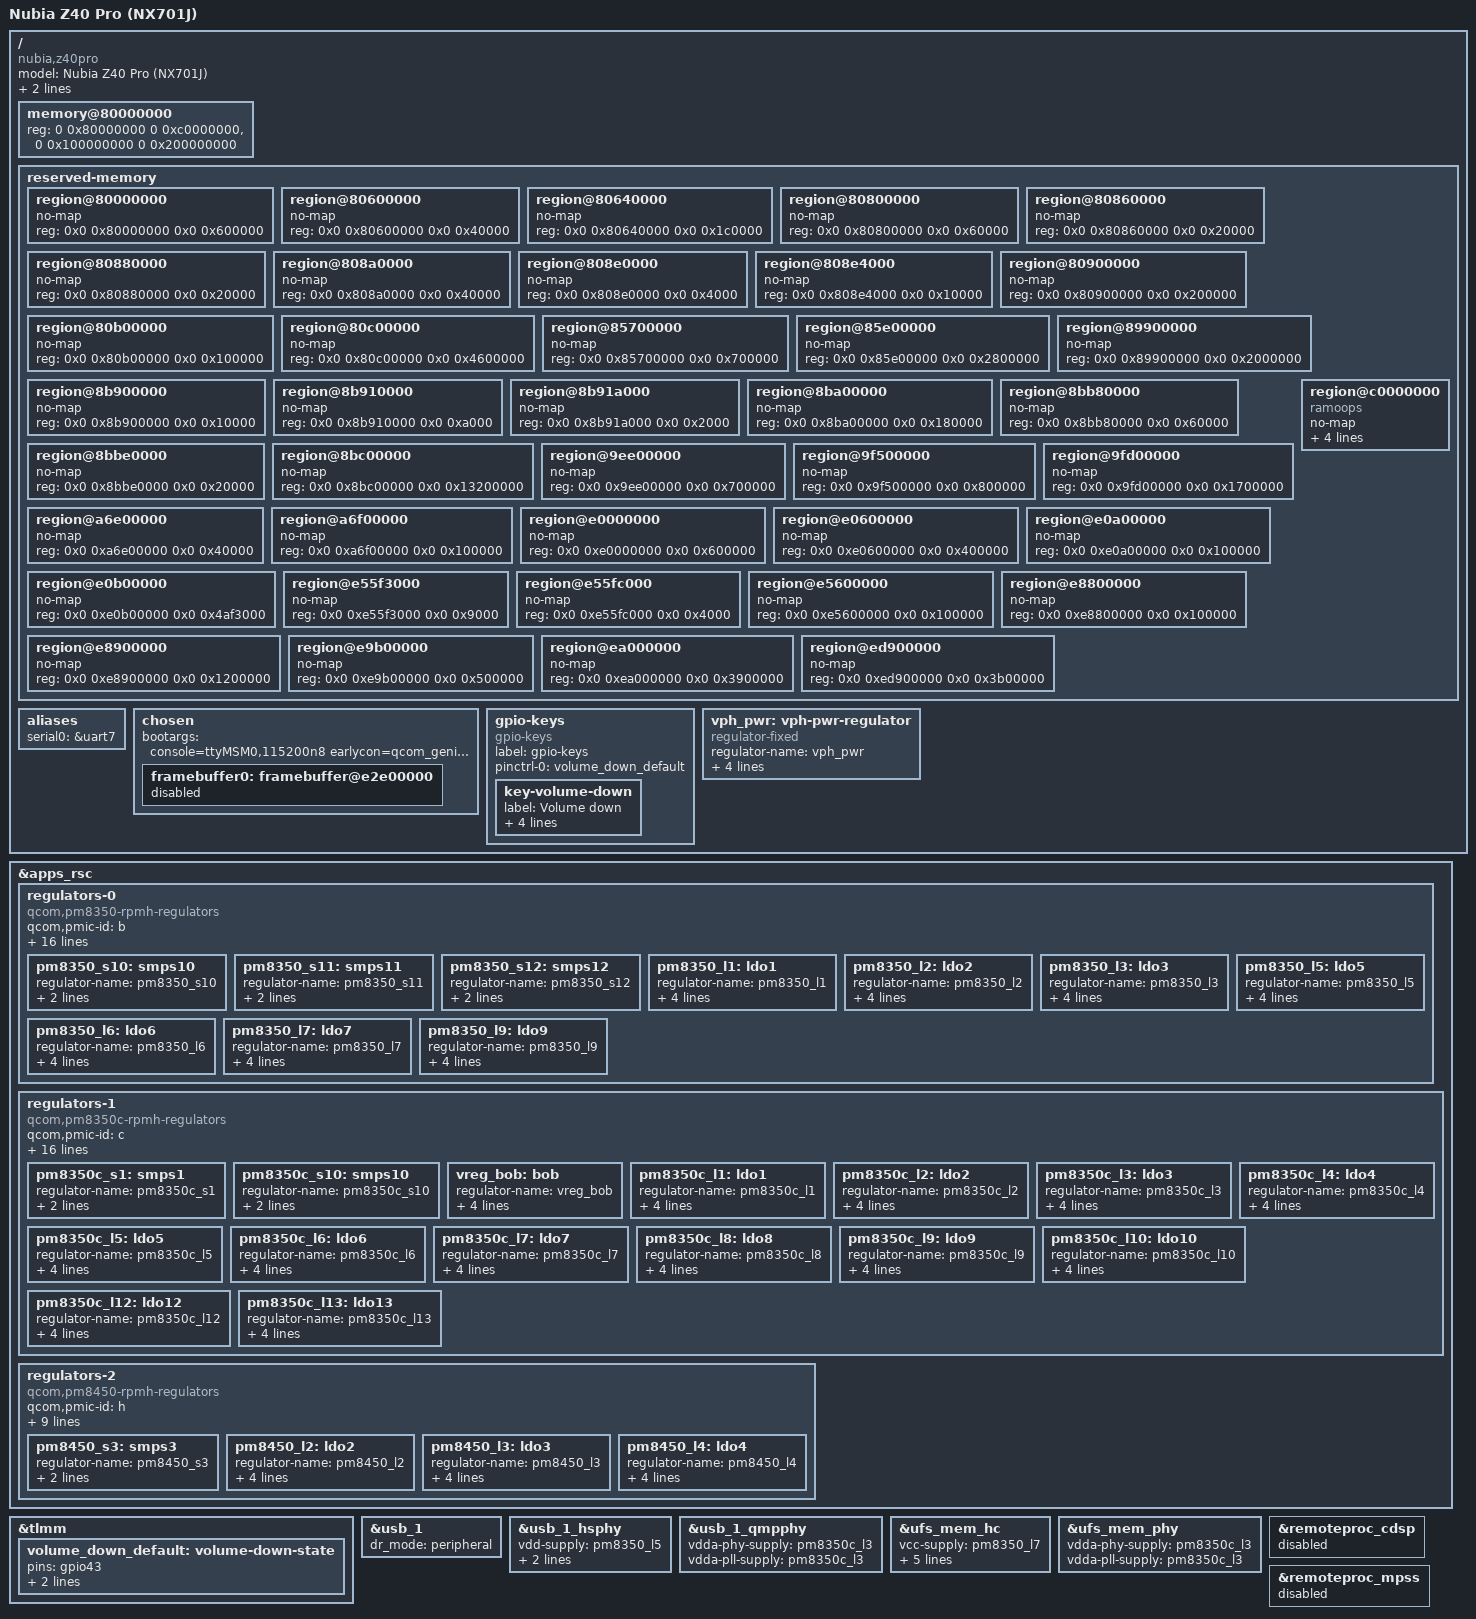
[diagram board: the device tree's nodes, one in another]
// SPDX-License-Identifier: BSD-3-Clause
/*
 * Nubia Z40 Pro (NX701J) — 骁龙8 Gen 1 (SM8450)
 * 底稿: sm8450-sony-xperia-nagara.dtsi (同平台手机模板)
 * 面板: Visionox RM692E5 1080p DSC cmd (mainline panel-visionox-rm692e5, M5 点亮)
 * 触摸: FocalTech (M5 移植)
 * v0.1 目标: USB/UFS 心跳 — 不含面板/触摸/音频/相机
 */

/dts-v1/;

#include "sm8450.dtsi"
#include "pm8350.dtsi"
#include "pm8350b.dtsi"
#include "pm8350c.dtsi"
#include "pm8450.dtsi"
#include <dt-bindings/input/linux-event-codes.h>
#include <dt-bindings/regulator/qcom,rpmh-regulator.h>

/ {
	model = "Nubia Z40 Pro (NX701J)";
	compatible = "nubia,z40pro", "qcom,sm8450";

	/* ZTE ABL 板级匹配必需 (从 MyOS cape DT 提取) */
	qcom,msm-id = <0x21c 0x10000>;
	qcom,board-id = <0x0 0x0>;

	memory@80000000 {
		device_type = "memory";
		/* Z40 Pro 12GB: 3GB @0x80000000 + 8GB @0x100000000 */
		reg = <0 0x80000000 0 0xc0000000>,
		      <0 0x100000000 0 0x200000000>;
	};

	reserved-memory {
		#address-cells = <2>;
		#size-cells = <2>;
		ranges;

		region@80000000 {
			no-map;
			reg = <0x0 0x80000000 0x0 0x600000>;
		};

		region@80600000 {
			no-map;
			reg = <0x0 0x80600000 0x0 0x40000>;
		};

		region@80640000 {
			no-map;
			reg = <0x0 0x80640000 0x0 0x1c0000>;
		};

		region@80800000 {
			no-map;
			reg = <0x0 0x80800000 0x0 0x60000>;
		};

		region@80860000 {
			no-map;
			reg = <0x0 0x80860000 0x0 0x20000>;
		};

		region@80880000 {
			no-map;
			reg = <0x0 0x80880000 0x0 0x20000>;
		};

		region@808a0000 {
			no-map;
			reg = <0x0 0x808a0000 0x0 0x40000>;
		};

		region@808e0000 {
			no-map;
			reg = <0x0 0x808e0000 0x0 0x4000>;
		};

		region@808e4000 {
			no-map;
			reg = <0x0 0x808e4000 0x0 0x10000>;
		};

		region@80900000 {
			no-map;
			reg = <0x0 0x80900000 0x0 0x200000>;
		};

		region@80b00000 {
			no-map;
			reg = <0x0 0x80b00000 0x0 0x100000>;
		};

		region@80c00000 {
			no-map;
			reg = <0x0 0x80c00000 0x0 0x4600000>;
		};

		region@85700000 {
			no-map;
			reg = <0x0 0x85700000 0x0 0x700000>;
		};

		region@85e00000 {
			no-map;
			reg = <0x0 0x85e00000 0x0 0x2800000>;
		};

		region@89900000 {
			no-map;
			reg = <0x0 0x89900000 0x0 0x2000000>;
		};

		region@8b900000 {
			no-map;
			reg = <0x0 0x8b900000 0x0 0x10000>;
		};

		region@8b910000 {
			no-map;
			reg = <0x0 0x8b910000 0x0 0xa000>;
		};

		region@8b91a000 {
			no-map;
			reg = <0x0 0x8b91a000 0x0 0x2000>;
		};

		region@8ba00000 {
			no-map;
			reg = <0x0 0x8ba00000 0x0 0x180000>;
		};

		region@8bb80000 {
			no-map;
			reg = <0x0 0x8bb80000 0x0 0x60000>;
		};

		region@8bbe0000 {
			no-map;
			reg = <0x0 0x8bbe0000 0x0 0x20000>;
		};

		region@8bc00000 {
			no-map;
			reg = <0x0 0x8bc00000 0x0 0x13200000>;
		};

		region@9ee00000 {
			no-map;
			reg = <0x0 0x9ee00000 0x0 0x700000>;
		};

		region@9f500000 {
			no-map;
			reg = <0x0 0x9f500000 0x0 0x800000>;
		};

		region@9fd00000 {
			no-map;
			reg = <0x0 0x9fd00000 0x0 0x1700000>;
		};

		region@a6e00000 {
			no-map;
			reg = <0x0 0xa6e00000 0x0 0x40000>;
		};

		region@a6f00000 {
			no-map;
			reg = <0x0 0xa6f00000 0x0 0x100000>;
		};

		region@c0000000 {
			compatible = "ramoops";
			no-map;
			reg = <0x0 0xc0000000 0x0 0x200000>;
			console-size = <0x40000>;
			record-size = <0x1000>;
			ecc-size = <16>;
		};

		region@e0000000 {
			no-map;
			reg = <0x0 0xe0000000 0x0 0x600000>;
		};

		region@e0600000 {
			no-map;
			reg = <0x0 0xe0600000 0x0 0x400000>;
		};

		region@e0a00000 {
			no-map;
			reg = <0x0 0xe0a00000 0x0 0x100000>;
		};

		region@e0b00000 {
			no-map;
			reg = <0x0 0xe0b00000 0x0 0x4af3000>;
		};

		region@e55f3000 {
			no-map;
			reg = <0x0 0xe55f3000 0x0 0x9000>;
		};

		region@e55fc000 {
			no-map;
			reg = <0x0 0xe55fc000 0x0 0x4000>;
		};

		region@e5600000 {
			no-map;
			reg = <0x0 0xe5600000 0x0 0x100000>;
		};

		region@e8800000 {
			no-map;
			reg = <0x0 0xe8800000 0x0 0x100000>;
		};

		region@e8900000 {
			no-map;
			reg = <0x0 0xe8900000 0x0 0x1200000>;
		};

		region@e9b00000 {
			no-map;
			reg = <0x0 0xe9b00000 0x0 0x500000>;
		};

		region@ea000000 {
			no-map;
			reg = <0x0 0xea000000 0x0 0x3900000>;
		};

		region@ed900000 {
			no-map;
			reg = <0x0 0xed900000 0x0 0x3b00000>;
		};

	};

	aliases {
		serial0 = &uart7;   /* TODO: 确认 Z40 Pro debug uart 实际编号 */
	};

	chosen {
		#address-cells = <1>;
		#size-cells = <1>;
		ranges;
		/* ZTE ABL 的 cmdline 被内建 DTB 覆盖丢弃, bootargs 必须在此 */
		bootargs = "console=ttyMSM0,115200n8 earlycon=qcom_geni,0xa90000 panic=10 loglevel=7 keep_bootcon z40pro.fb=0xB8000000,4320,2400,1080,32";

		framebuffer0: framebuffer@e2e00000 {
			status = "disabled";   /* M5 点亮后启用 */
		};
	};

	/* 音量下键 — GPIO 编号待从 MyOS 运行时确认 (M4 补), 先留壳 */
	gpio-keys {
		compatible = "gpio-keys";
		label = "gpio-keys";
		pinctrl-names = "default";
		pinctrl-0 = <&volume_down_default>;

		key-volume-down {
			label = "Volume down";
			linux,code = <KEY_VOLUMEDOWN>;
			gpios = <&tlmm 43 GPIO_ACTIVE_LOW>;   /* TODO: 校准 */
			debounce-interval = <15>;
			wakeup-source;
		};
	};

	vph_pwr: vph-pwr-regulator {
		compatible = "regulator-fixed";
		regulator-name = "vph_pwr";
		regulator-min-microvolt = <3700000>;
		regulator-max-microvolt = <3700000>;
		regulator-always-on;
		regulator-boot-on;
	};
};

&apps_rsc {
	regulators-0 {
		compatible = "qcom,pm8350-rpmh-regulators";
		qcom,pmic-id = "b";

		vdd-s1-supply = <&vph_pwr>;
		vdd-s2-supply = <&vph_pwr>;
		vdd-s3-supply = <&vph_pwr>;
		vdd-s4-supply = <&vph_pwr>;
		vdd-s5-supply = <&vph_pwr>;
		vdd-s6-supply = <&vph_pwr>;
		vdd-s7-supply = <&vph_pwr>;
		vdd-s8-supply = <&vph_pwr>;
		vdd-s9-supply = <&vph_pwr>;
		vdd-s10-supply = <&vph_pwr>;
		vdd-s11-supply = <&vph_pwr>;
		vdd-s12-supply = <&vph_pwr>;

		vdd-l1-l4-supply = <&pm8350_s11>;
		vdd-l2-l7-supply = <&vreg_bob>;
		vdd-l3-l5-supply = <&vreg_bob>;
		vdd-l6-l9-l10-supply = <&pm8350_s12>;

		pm8350_s10: smps10 {
			regulator-name = "pm8350_s10";
			regulator-min-microvolt = <1800000>;
			regulator-max-microvolt = <1800000>;
		};

		pm8350_s11: smps11 {
			regulator-name = "pm8350_s11";
			regulator-min-microvolt = <848000>;
			regulator-max-microvolt = <1104000>;
		};

		pm8350_s12: smps12 {
			regulator-name = "pm8350_s12";
			regulator-min-microvolt = <1224000>;
			regulator-max-microvolt = <1400000>;
		};

		pm8350_l1: ldo1 {
			regulator-name = "pm8350_l1";
			regulator-min-microvolt = <912000>;
			regulator-max-microvolt = <920000>;
			regulator-initial-mode = <RPMH_REGULATOR_MODE_HPM>;
		};

		pm8350_l2: ldo2 {
			regulator-name = "pm8350_l2";
			regulator-min-microvolt = <3072000>;
			regulator-max-microvolt = <3072000>;
			regulator-initial-mode = <RPMH_REGULATOR_MODE_HPM>;
		};

		pm8350_l3: ldo3 {
			regulator-name = "pm8350_l3";
			regulator-min-microvolt = <904000>;
			regulator-max-microvolt = <904000>;
			regulator-initial-mode = <RPMH_REGULATOR_MODE_HPM>;
		};

		pm8350_l5: ldo5 {
			regulator-name = "pm8350_l5";
			regulator-min-microvolt = <880000>;
			regulator-max-microvolt = <912000>;
			regulator-initial-mode = <RPMH_REGULATOR_MODE_HPM>;
		};

		pm8350_l6: ldo6 {
			regulator-name = "pm8350_l6";
			regulator-min-microvolt = <1200000>;
			regulator-max-microvolt = <1200000>;
			regulator-initial-mode = <RPMH_REGULATOR_MODE_HPM>;
		};

		pm8350_l7: ldo7 {
			regulator-name = "pm8350_l7";
			regulator-min-microvolt = <2960000>;   /* TODO: Z40 Pro 实测校准 (UFS vcc) */
			regulator-max-microvolt = <2960000>;
			regulator-initial-mode = <RPMH_REGULATOR_MODE_HPM>;
		};

		pm8350_l9: ldo9 {
			regulator-name = "pm8350_l9";
			regulator-min-microvolt = <1200000>;
			regulator-max-microvolt = <1200000>;
			regulator-initial-mode = <RPMH_REGULATOR_MODE_HPM>;
		};
	};

	regulators-1 {
		compatible = "qcom,pm8350c-rpmh-regulators";
		qcom,pmic-id = "c";

		vdd-s1-supply = <&vph_pwr>;
		vdd-s2-supply = <&vph_pwr>;
		vdd-s3-supply = <&vph_pwr>;
		vdd-s4-supply = <&vph_pwr>;
		vdd-s5-supply = <&vph_pwr>;
		vdd-s6-supply = <&vph_pwr>;
		vdd-s7-supply = <&vph_pwr>;
		vdd-s8-supply = <&vph_pwr>;
		vdd-s9-supply = <&vph_pwr>;
		vdd-s10-supply = <&vph_pwr>;

		vdd-l1-l12-supply = <&vreg_bob>;
		vdd-l2-l8-supply = <&vreg_bob>;
		vdd-l3-l4-l5-l7-l13-supply = <&vreg_bob>;
		vdd-l6-l9-l11-supply = <&vreg_bob>;
		vdd-l10-supply = <&pm8350_s12>;

		vdd-bob-supply = <&vph_pwr>;

		pm8350c_s1: smps1 {
			regulator-name = "pm8350c_s1";
			regulator-min-microvolt = <1800000>;
			regulator-max-microvolt = <2024000>;
		};

		pm8350c_s10: smps10 {
			regulator-name = "pm8350c_s10";
			regulator-min-microvolt = <1000000>;
			regulator-max-microvolt = <1100000>;
		};

		vreg_bob: bob {
			regulator-name = "vreg_bob";
			regulator-min-microvolt = <3400000>;
			regulator-max-microvolt = <3960000>;
			regulator-initial-mode = <RPMH_REGULATOR_MODE_AUTO>;
		};

		pm8350c_l1: ldo1 {
			regulator-name = "pm8350c_l1";
			regulator-min-microvolt = <1800000>;
			regulator-max-microvolt = <1800000>;
			regulator-initial-mode = <RPMH_REGULATOR_MODE_HPM>;
		};

		pm8350c_l2: ldo2 {
			regulator-name = "pm8350c_l2";
			regulator-min-microvolt = <1800000>;
			regulator-max-microvolt = <1800000>;
			regulator-initial-mode = <RPMH_REGULATOR_MODE_HPM>;
		};

		pm8350c_l3: ldo3 {
			regulator-name = "pm8350c_l3";
			regulator-min-microvolt = <3296000>;
			regulator-max-microvolt = <3304000>;
			regulator-initial-mode = <RPMH_REGULATOR_MODE_HPM>;
		};

		pm8350c_l4: ldo4 {
			regulator-name = "pm8350c_l4";
			regulator-min-microvolt = <1704000>;
			regulator-max-microvolt = <3000000>;
			regulator-initial-mode = <RPMH_REGULATOR_MODE_HPM>;
		};

		pm8350c_l5: ldo5 {
			regulator-name = "pm8350c_l5";
			regulator-min-microvolt = <1704000>;
			regulator-max-microvolt = <3000000>;
			regulator-initial-mode = <RPMH_REGULATOR_MODE_HPM>;
		};

		pm8350c_l6: ldo6 {
			regulator-name = "pm8350c_l6";
			regulator-min-microvolt = <2960000>;
			regulator-max-microvolt = <2960000>;
			regulator-initial-mode = <RPMH_REGULATOR_MODE_HPM>;
		};

		pm8350c_l7: ldo7 {
			regulator-name = "pm8350c_l7";
			regulator-min-microvolt = <3008000>;
			regulator-max-microvolt = <3008000>;
			regulator-initial-mode = <RPMH_REGULATOR_MODE_HPM>;
		};

		pm8350c_l8: ldo8 {
			regulator-name = "pm8350c_l8";
			regulator-min-microvolt = <1800000>;
			regulator-max-microvolt = <1800000>;
			regulator-initial-mode = <RPMH_REGULATOR_MODE_HPM>;
		};

		pm8350c_l9: ldo9 {
			regulator-name = "pm8350c_l9";
			regulator-min-microvolt = <2960000>;
			regulator-max-microvolt = <2960000>;
			regulator-initial-mode = <RPMH_REGULATOR_MODE_HPM>;
		};

		pm8350c_l10: ldo10 {
			regulator-name = "pm8350c_l10";
			regulator-min-microvolt = <1200000>;
			regulator-max-microvolt = <1200000>;
			regulator-initial-mode = <RPMH_REGULATOR_MODE_HPM>;
		};

		pm8350c_l12: ldo12 {
			regulator-name = "pm8350c_l12";
			regulator-min-microvolt = <1800000>;
			regulator-max-microvolt = <1968000>;
			regulator-initial-mode = <RPMH_REGULATOR_MODE_HPM>;
		};

		pm8350c_l13: ldo13 {
			regulator-name = "pm8350c_l13";
			regulator-min-microvolt = <3000000>;
			regulator-max-microvolt = <3000000>;
			regulator-initial-mode = <RPMH_REGULATOR_MODE_HPM>;
		};
	};

	regulators-2 {
		compatible = "qcom,pm8450-rpmh-regulators";
		qcom,pmic-id = "h";

		vdd-s1-supply = <&vph_pwr>;
		vdd-s2-supply = <&vph_pwr>;
		vdd-s3-supply = <&vph_pwr>;
		vdd-s4-supply = <&vph_pwr>;
		vdd-s5-supply = <&vph_pwr>;
		vdd-s6-supply = <&vph_pwr>;

		vdd-l2-supply = <&vreg_bob>;
		vdd-l3-supply = <&vreg_bob>;
		vdd-l4-supply = <&vreg_bob>;

		pm8450_s3: smps3 {
			regulator-name = "pm8450_s3";
			regulator-min-microvolt = <500000>;
			regulator-max-microvolt = <600000>;
		};

		pm8450_l2: ldo2 {
			regulator-name = "pm8450_l2";
			regulator-min-microvolt = <880000>;
			regulator-max-microvolt = <912000>;
			regulator-initial-mode = <RPMH_REGULATOR_MODE_HPM>;
		};

		pm8450_l3: ldo3 {
			regulator-name = "pm8450_l3";
			regulator-min-microvolt = <912000>;
			regulator-max-microvolt = <912000>;
			regulator-initial-mode = <RPMH_REGULATOR_MODE_HPM>;
		};

		pm8450_l4: ldo4 {
			regulator-name = "pm8450_l4";
			regulator-min-microvolt = <784000>;
			regulator-max-microvolt = <912000>;
			regulator-initial-mode = <RPMH_REGULATOR_MODE_HPM>;
		};
	};

	/* TODO: pm8350b (spmi pm8350b@3) — Z40 Pro 有第四组 PMIC, 电压表待从 MyOS 提取 */
};

&tlmm {
	volume_down_default: volume-down-state {
		pins = "gpio43";   /* TODO: 校准 */
		function = "gpio";
		bias-pull-up;
	};
};

/* USB — 心跳生命线 (M4: initramfs gadget NCM + ssh) */
&usb_1 {
	status = "okay";
	dr_mode = "peripheral";   /* 手机口: PC 直连 */
};

&usb_1_hsphy {
	status = "okay";
	vdd-supply = <&pm8350_l5>;   /* TODO: 校准实际供电 */
	vdda-pll-supply = <&pm8350c_l3>;
	vdda-phy-supply = <&pm8350c_l3>;
};

&usb_1_qmpphy {
	status = "okay";
	vdda-phy-supply = <&pm8350c_l3>;
	vdda-pll-supply = <&pm8350c_l3>;
};

/* UFS — rootfs 载体 */
&ufs_mem_hc {
	status = "okay";
	vcc-supply = <&pm8350_l7>;
	vcc-max-microamp = <800000>;
	vccq-supply = <&pm8350_l9>;
	vccq-max-microamp = <900000>;
	vccq2-supply = <&pm8350c_l9>;
	vccq2-max-microamp = <900000>;
};

&ufs_mem_phy {
	status = "okay";
	vdda-phy-supply = <&pm8350c_l3>;
	vdda-pll-supply = <&pm8350c_l3>;
};

/* TODO: remoteproc (modem/dsp) 状态待心跳验证后处理 */

&remoteproc_cdsp {
	status = "disabled";
};

&remoteproc_mpss {
	status = "disabled";
};

